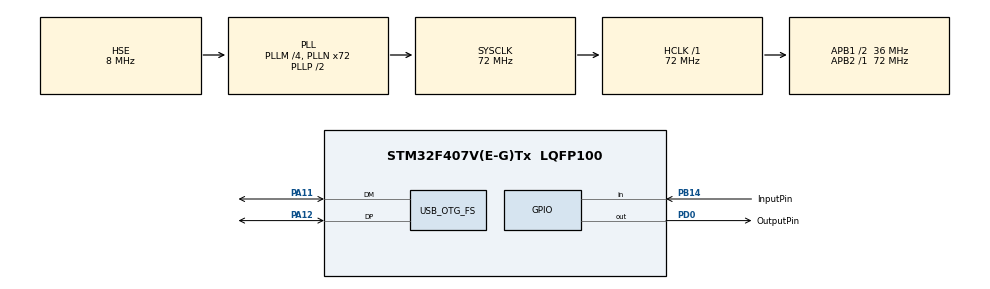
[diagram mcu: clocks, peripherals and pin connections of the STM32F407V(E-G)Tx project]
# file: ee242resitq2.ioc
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Mcu.Family=STM32F4
Mcu.Name=STM32F407V(E-G)Tx
Mcu.Package=LQFP100
NVIC.OTG_FS_IRQn=true\:0\:0\:false\:false\:true\:false\:true\:true
NVIC.PriorityGroup=NVIC_PRIORITYGROUP_4
PA11.Mode=Device_Only
PA11.Signal=USB_OTG_FS_DM
PA12.Mode=Device_Only
PA12.Signal=USB_OTG_FS_DP
PB14.GPIO_Label=InputPin
PB14.GPIO_PuPd=GPIO_PULLUP
PB14.Signal=GPIO_Input
PD0.GPIO_Label=OutputPin
PD0.Signal=GPIO_Output
PH0-OSC_IN.Mode=HSE-External-Oscillator
PH0-OSC_IN.Signal=RCC_OSC_IN
PH1-OSC_OUT.Mode=HSE-External-Oscillator
PH1-OSC_OUT.Signal=RCC_OSC_OUT
ProjectManager.HeapSize=0x200
ProjectManager.StackSize=0x400
ProjectManager.TargetToolchain=STM32CubeIDE
RCC.48MHZClocksFreq_Value=48000000
RCC.AHBFreq_Value=72000000
RCC.APB1CLKDivider=RCC_HCLK_DIV2
RCC.APB1Freq_Value=36000000
RCC.APB1TimFreq_Value=72000000
RCC.APB2Freq_Value=72000000
RCC.APB2TimFreq_Value=72000000
RCC.CortexFreq_Value=72000000
RCC.HCLKFreq_Value=72000000
RCC.HSE_VALUE=8000000
RCC.HSI_VALUE=16000000
RCC.LSE_VALUE=32768
RCC.PLLM=4
RCC.PLLN=72
RCC.PLLQ=3
RCC.SYSCLKFreq_VALUE=72000000
RCC.SYSCLKSource=RCC_SYSCLKSOURCE_PLLCLK
RCC.VCOOutputFreq_Value=144000000
USB_DEVICE.CLASS_NAME_FS=CDC
USB_DEVICE.VirtualMode-CDC_FS=Cdc
USB_DEVICE.VirtualModeFS=Cdc_FS
USB_OTG_FS.VirtualMode=Device_Only
VP_USB_DEVICE_VS_USB_DEVICE_CDC_FS.Mode=CDC_FS
board=custom

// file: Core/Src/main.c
/* USER CODE BEGIN Header */
/**
  ******************************************************************************
  * @file           : main.c
  * @brief          : Main program body
  ******************************************************************************
  * @attention
  *
  * Copyright (c) 2023 STMicroelectronics.
  * All rights reserved.
  *
  * This software is licensed under terms that can be found in the LICENSE file
  * in the root directory of this software component.
  * If no LICENSE file comes with this software, it is provided AS-IS.
  *
  ******************************************************************************
  */
/* USER CODE END Header */
#include "main.h"
#include "usb_device.h"

void SystemClock_Config(void);
static void MX_GPIO_Init(void);

/* USER CODE BEGIN 0 */
uint8_t buffer[64];
int readvalue;
int readvalues[8] = {0,0,0,0,0,0,0,0};

int bit0;
int bit1;
int bit2;
int bit3;
int bit4;
int bit5;
int bit6;
int bit7;
/* USER CODE END 0 */

int main(void)
{

  /* MCU Configuration--------------------------------------------------------*/

  /* Reset of all peripherals, Initializes the Flash interface and the Systick. */
  HAL_Init();

  /* Configure the system clock */
  SystemClock_Config();

  /* Initialize all configured peripherals */
  MX_GPIO_Init();
  MX_USB_DEVICE_Init();

  /* Infinite loop */
  while (1)
  {
	  if(buffer[0] != '\0'){
	  		  char c = buffer[0];
	  		  int num = c;
	  		  int j = 0;
	  		  int a[8];
	  		  int multby = 1;
	  		  int finalvalue = 0;
	  		  for( j = 0; j<8; j++){
	  			  a[j] = num%2;
	  			  num=num/2;
	  			  printf("a[%d]=%d\n",j,a[j]);
	  			  HAL_GPIO_WritePin(GPIOD,OutputPin_Pin,a[j]);
	  			  HAL_Delay(100);
	  			  readvalue = HAL_GPIO_ReadPin(GPIOB,InputPin_Pin);
	  			  readvalues[j] = readvalue;
	  			  finalvalue = finalvalue+multby*readvalue;
	  			  multby=multby*2;
	  			  HAL_Delay(100);
	  		  }

	  		 bit0= readvalues[0];
	  		 bit1= readvalues[1]*2;
	  		 bit2= readvalues[2]*4;
	  		 bit3= readvalues[3]*8;
	  		 bit4= readvalues[4]*16;
	  		 bit5= readvalues[5]*32;
	  		 bit6= readvalues[6]*64;
	  		 bit7= readvalues[7]*128;

	  		char* chartosend = &finalvalue;

	  		CDC_Transmit_FS((uint8_t*) chartosend, strlen(chartosend));

	  }
  }
}

void SystemClock_Config(void)
{
  RCC_OscInitTypeDef RCC_OscInitStruct = {0};
  RCC_ClkInitTypeDef RCC_ClkInitStruct = {0};

  /** Configure the main internal regulator output voltage
  */
  __HAL_RCC_PWR_CLK_ENABLE();
  __HAL_PWR_VOLTAGESCALING_CONFIG(PWR_REGULATOR_VOLTAGE_SCALE1);

  /** Initializes the RCC Oscillators according to the specified parameters
  * in the RCC_OscInitTypeDef structure.
  */
  RCC_OscInitStruct.OscillatorType = RCC_OSCILLATORTYPE_HSE;
  RCC_OscInitStruct.HSEState = RCC_HSE_ON;
  RCC_OscInitStruct.PLL.PLLState = RCC_PLL_ON;
  RCC_OscInitStruct.PLL.PLLSource = RCC_PLLSOURCE_HSE;
  RCC_OscInitStruct.PLL.PLLM = 4;
  RCC_OscInitStruct.PLL.PLLN = 72;
  RCC_OscInitStruct.PLL.PLLP = RCC_PLLP_DIV2;
  RCC_OscInitStruct.PLL.PLLQ = 3;
  if (HAL_RCC_OscConfig(&RCC_OscInitStruct) != HAL_OK)
  {
    Error_Handler();
  }

  /** Initializes the CPU, AHB and APB buses clocks
  */
  RCC_ClkInitStruct.ClockType = RCC_CLOCKTYPE_HCLK|RCC_CLOCKTYPE_SYSCLK
                              |RCC_CLOCKTYPE_PCLK1|RCC_CLOCKTYPE_PCLK2;
  RCC_ClkInitStruct.SYSCLKSource = RCC_SYSCLKSOURCE_PLLCLK;
  RCC_ClkInitStruct.AHBCLKDivider = RCC_SYSCLK_DIV1;
  RCC_ClkInitStruct.APB1CLKDivider = RCC_HCLK_DIV2;
  RCC_ClkInitStruct.APB2CLKDivider = RCC_HCLK_DIV1;

  if (HAL_RCC_ClockConfig(&RCC_ClkInitStruct, FLASH_LATENCY_2) != HAL_OK)
  {
    Error_Handler();
  }
}

static void MX_GPIO_Init(void)
{
  GPIO_InitTypeDef GPIO_InitStruct = {0};

  /* GPIO Ports Clock Enable */
  __HAL_RCC_GPIOH_CLK_ENABLE();
  __HAL_RCC_GPIOB_CLK_ENABLE();
  __HAL_RCC_GPIOA_CLK_ENABLE();
  __HAL_RCC_GPIOD_CLK_ENABLE();

  /*Configure GPIO pin Output Level */
  HAL_GPIO_WritePin(OutputPin_GPIO_Port, OutputPin_Pin, GPIO_PIN_RESET);

  /*Configure GPIO pin : InputPin_Pin */
  GPIO_InitStruct.Pin = InputPin_Pin;
  GPIO_InitStruct.Mode = GPIO_MODE_INPUT;
  GPIO_InitStruct.Pull = GPIO_PULLUP;
  HAL_GPIO_Init(InputPin_GPIO_Port, &GPIO_InitStruct);

  /*Configure GPIO pin : OutputPin_Pin */
  GPIO_InitStruct.Pin = OutputPin_Pin;
  GPIO_InitStruct.Mode = GPIO_MODE_OUTPUT_PP;
  GPIO_InitStruct.Pull = GPIO_NOPULL;
  GPIO_InitStruct.Speed = GPIO_SPEED_FREQ_LOW;
  HAL_GPIO_Init(OutputPin_GPIO_Port, &GPIO_InitStruct);

}

void Error_Handler(void)
{
  __disable_irq();
  while (1)
  {
  }
}
